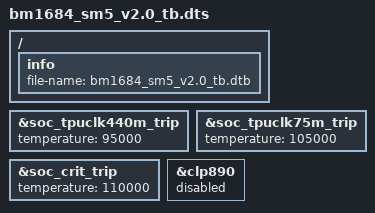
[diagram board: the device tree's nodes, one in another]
#include "bm1684.dtsi"
#include "bm1684_mm_16g.dtsi"
#include "bm1684_sm5_tb.dtsi"

/ {
	info {
		file-name = "bm1684_sm5_v2.0_tb.dtb";
	};
};

&soc_tpuclk440m_trip {
	temperature = <95000>;
};

&soc_tpuclk75m_trip {
	temperature = <105000>;
};

&soc_crit_trip {
	temperature = <110000>;
};

&clp890 {
	status = "disabled";
};
